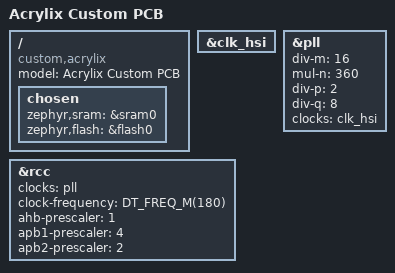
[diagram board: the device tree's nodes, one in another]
/dts-v1/;

#include <st/f4/stm32f446Xe.dtsi>
#include <st/f4/stm32f446r(c-e)tx-pinctrl.dtsi>
#include <zephyr/dt-bindings/input/input-event-codes.h>

/ {
    model = "Acrylix Custom PCB";
    compatible = "custom,acrylix";

    chosen {
        zephyr,sram  = &sram0;
        zephyr,flash = &flash0;
    };
};

/* ── Clocks: HSI (16 MHz) → PLL → 180 MHz SYSCLK ── */
&clk_hsi {
    status = "okay";
};

&pll {
    div-m = <16>;
    mul-n = <360>;
    div-p = <2>;
    div-q = <8>;
    clocks = <&clk_hsi>;
    status = "okay";
};

&rcc {
    clocks = <&pll>;
    clock-frequency = <DT_FREQ_M(180)>;
    ahb-prescaler  = <1>;
    apb1-prescaler = <4>;   /* APB1 max 45 MHz → 180/4 = 45 MHz */
    apb2-prescaler = <2>;   /* APB2 max 90 MHz → 180/2 = 90 MHz */
};
